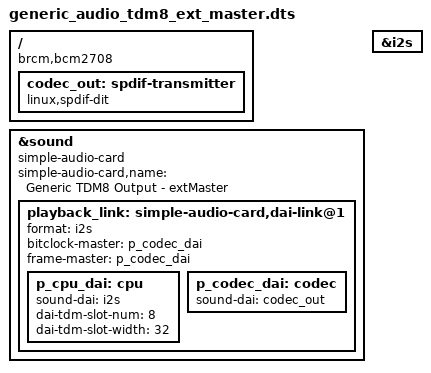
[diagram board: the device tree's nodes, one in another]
// Device Tree Overlay for generic TDM8 audio output
// Raspberry outputs 2 audio channels arranged in tdm8 format, 32 bit, 2 channels, bclk = 256 x fs

/dts-v1/;
/plugin/;

/ {
    compatible = "brcm,bcm2708";

    fragment@0 {
        target = <&sound>;
        __overlay__ {

            compatible = "simple-audio-card";
            simple-audio-card,name = "Generic TDM8 Output - extMaster";
			
            status="okay";

            playback_link: simple-audio-card,dai-link@1 {
                format = "i2s";
				
		bitclock-master = <&p_codec_dai>;
                frame-master = <&p_codec_dai>;

                p_cpu_dai: cpu {
                    sound-dai = <&i2s>;

		    //TDM slot configuration - BCLK ratio: 256 x Fs
                    dai-tdm-slot-num = <8>;
                    dai-tdm-slot-width = <32>;
                
				};

                p_codec_dai: codec {
                    sound-dai = <&codec_out>;
                };
            };
        };
    };

    fragment@1 {
        target-path = "/";
        __overlay__ {
            codec_out: spdif-transmitter {
                #address-cells = <0>;
                #size-cells = <0>;
                #sound-dai-cells = <0>;
                compatible = "linux,spdif-dit";
                status = "okay";
            };
        };
    };

    fragment@2 {
        target = <&i2s>;
        __overlay__ {
            #sound-dai-cells = <0>;
            status = "okay";
        };
    };
};
